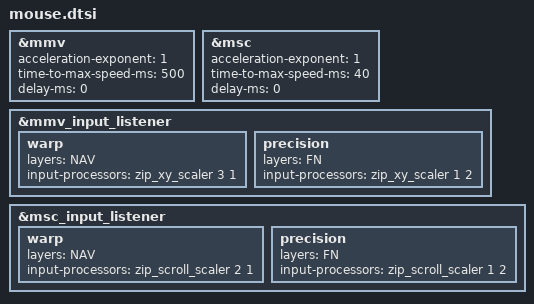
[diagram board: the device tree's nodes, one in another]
// ZMK renamed this subsystem from "mouse" to "pointing". The macro names below
// must be ZMK_POINTING_* -- pointing.h no longer reads the old ZMK_MOUSE_*
// names, so those would be silently ignored and fall back to the stock
// defaults (600 move / 10 scroll).
#define ZMK_POINTING_DEFAULT_MOVE_VAL 1500  // 600
#define ZMK_POINTING_DEFAULT_SCRL_VAL 20    // 10

#include <dt-bindings/zmk/pointing.h>
#include <input/processors.dtsi>

// Config from @caksoylar, defaults in comments
&mmv {
  acceleration-exponent = <1>;      // 1
  time-to-max-speed-ms = <500>;     // 300
  delay-ms = <0>;                   // 0
};

&msc {
  acceleration-exponent = <1>;      // 0
  time-to-max-speed-ms = <40>;      // 300
  delay-ms = <0>;                   // 0
};

// Speed modes, applied while an extra layer is held on top of MOUSE. Both are
// driven from the left thumbs: NAV is the outer one (falls through from the
// base layer), FN is bound on the mouse layer's middle thumb. zip_xy_scaler
// and zip_scroll_scaler are ZMK built-ins; the two cells are multiplier and
// divisor, and they track remainders so a halved small movement is not
// truncated to zero.
&mmv_input_listener {
  warp {
    layers = <NAV>;
    input-processors = <&zip_xy_scaler 3 1>;      // 3x
  };
  precision {
    layers = <FN>;
    input-processors = <&zip_xy_scaler 1 2>;      // half
  };
};

&msc_input_listener {
  warp {
    layers = <NAV>;
    input-processors = <&zip_scroll_scaler 2 1>;  // 2x
  };
  precision {
    layers = <FN>;
    input-processors = <&zip_scroll_scaler 1 2>;  // half
  };
};

#define U_MS_U &mmv MOVE_UP
#define U_MS_D &mmv MOVE_DOWN
#define U_MS_L &mmv MOVE_LEFT
#define U_MS_R &mmv MOVE_RIGHT
#define U_WH_U &msc SCRL_UP
#define U_WH_D &msc SCRL_DOWN
#define U_WH_L &msc SCRL_LEFT
#define U_WH_R &msc SCRL_RIGHT

